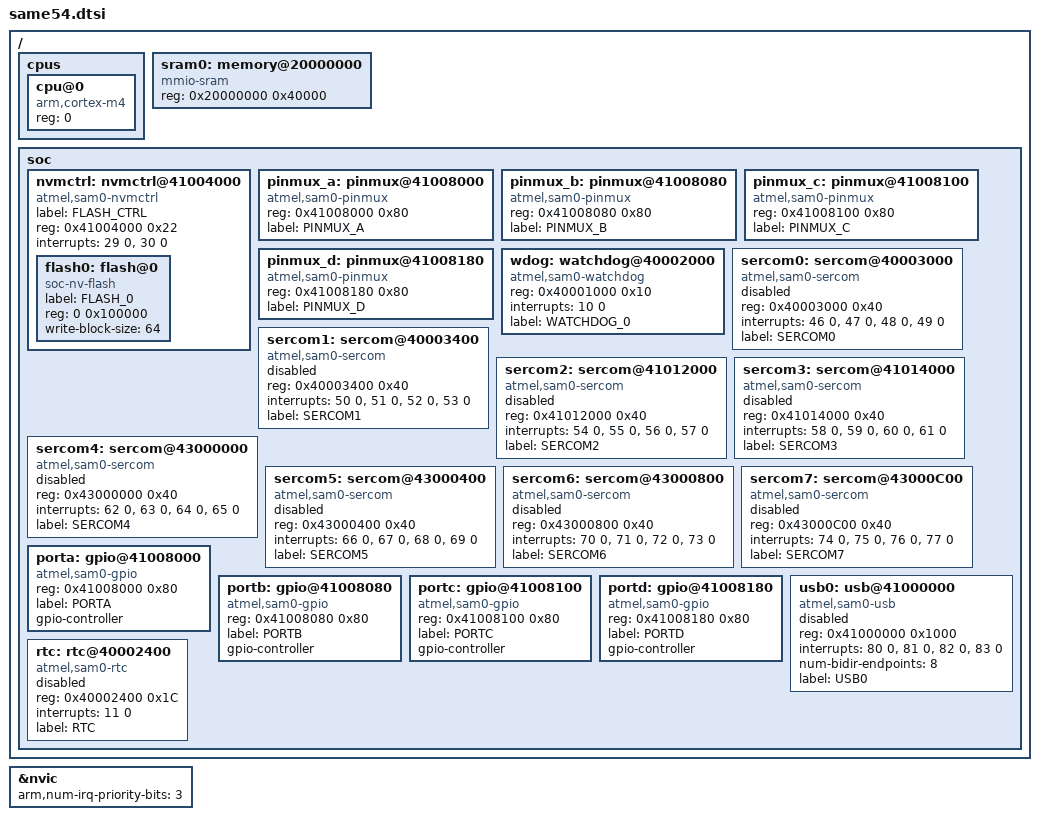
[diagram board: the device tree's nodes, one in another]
/*
 * Copyright (c) 2019 ML!PA Consulting GmbH
 *
 * SPDX-License-Identifier: Apache-2.0
 */

#include <arm/armv7-m.dtsi>
#include <dt-bindings/gpio/gpio.h>

/ {
	cpus {
		#address-cells = <1>;
		#size-cells = <0>;

		cpu@0 {
			device_type = "cpu";
			compatible = "arm,cortex-m4";
			reg = <0>;
		};
	};

	sram0: memory@20000000 {
		device_type = "memory";
		compatible = "mmio-sram";
		reg = <0x20000000 0x40000>;
	};

	soc {
		nvmctrl: nvmctrl@41004000  {
			compatible = "atmel,sam0-nvmctrl";
			label = "FLASH_CTRL";
			reg = <0x41004000 0x22>;
			interrupts = <29 0>, <30 0>;

			#address-cells = <1>;
			#size-cells = <1>;

			flash0: flash@0 {
				compatible = "soc-nv-flash";
				label = "FLASH_0";
				reg = <0 0x100000>;
				write-block-size = <64>;
			};
		};

		pinmux_a: pinmux@41008000 {
			compatible = "atmel,sam0-pinmux";
			reg = <0x41008000 0x80>;
			label = "PINMUX_A";
		};

		pinmux_b: pinmux@41008080 {
			compatible = "atmel,sam0-pinmux";
			reg = <0x41008080 0x80>;
			label = "PINMUX_B";
		};

		pinmux_c: pinmux@41008100 {
			compatible = "atmel,sam0-pinmux";
			reg = <0x41008100 0x80>;
			label = "PINMUX_C";
		};

		pinmux_d: pinmux@41008180 {
			compatible = "atmel,sam0-pinmux";
			reg = <0x41008180 0x80>;
			label = "PINMUX_D";
		};

		wdog: watchdog@40002000 {
			compatible = "atmel,sam0-watchdog";
			reg = <0x40001000 0x10>;
			interrupts = <10 0>;
			label = "WATCHDOG_0";
		};

		sercom0: sercom@40003000 {
			compatible = "atmel,sam0-sercom";
			reg = <0x40003000 0x40>;
			interrupts = <46 0>, <47 0>, <48 0>, <49 0>;
			status = "disabled";
			label = "SERCOM0";
		};

		sercom1: sercom@40003400 {
			compatible = "atmel,sam0-sercom";
			reg = <0x40003400 0x40>;
			interrupts = <50 0>, <51 0>, <52 0>, <53 0>;
			status = "disabled";
			label = "SERCOM1";
		};

		sercom2: sercom@41012000 {
			compatible = "atmel,sam0-sercom";
			reg = <0x41012000 0x40>;
			interrupts = <54 0>, <55 0>, <56 0>, <57 0>;
			status = "disabled";
			label = "SERCOM2";
		};

		sercom3: sercom@41014000 {
			compatible = "atmel,sam0-sercom";
			reg = <0x41014000 0x40>;
			interrupts = <58 0>, <59 0>, <60 0>, <61 0>;
			status = "disabled";
			label = "SERCOM3";
		};

		sercom4: sercom@43000000 {
			compatible = "atmel,sam0-sercom";
			reg = <0x43000000 0x40>;
			interrupts = <62 0>, <63 0>, <64 0>, <65 0>;
			status = "disabled";
			label = "SERCOM4";
		};

		sercom5: sercom@43000400 {
			compatible = "atmel,sam0-sercom";
			reg = <0x43000400 0x40>;
			interrupts = <66 0>, <67 0>, <68 0>, <69 0>;
			status = "disabled";
			label = "SERCOM5";
		};

		sercom6: sercom@43000800 {
			compatible = "atmel,sam0-sercom";
			reg = <0x43000800 0x40>;
			interrupts = <70 0>, <71 0>, <72 0>, <73 0>;
			status = "disabled";
			label = "SERCOM6";
		};

		sercom7: sercom@43000C00 {
			compatible = "atmel,sam0-sercom";
			reg = <0x43000C00 0x40>;
			interrupts = <74 0>, <75 0>, <76 0>, <77 0>;
			status = "disabled";
			label = "SERCOM7";
		};

		porta: gpio@41008000 {
			compatible = "atmel,sam0-gpio";
			reg = <0x41008000 0x80>;
			label = "PORTA";
			gpio-controller;
			#gpio-cells = <2>;
		};

		portb: gpio@41008080 {
			compatible = "atmel,sam0-gpio";
			reg = <0x41008080 0x80>;
			label = "PORTB";
			gpio-controller;
			#gpio-cells = <2>;
		};

		portc: gpio@41008100 {
			compatible = "atmel,sam0-gpio";
			reg = <0x41008100 0x80>;
			label = "PORTC";
			gpio-controller;
			#gpio-cells = <2>;
		};

		portd: gpio@41008180 {
			compatible = "atmel,sam0-gpio";
			reg = <0x41008180 0x80>;
			label = "PORTD";
			gpio-controller;
			#gpio-cells = <2>;
		};

		usb0: usb@41000000 {
			compatible = "atmel,sam0-usb";
			status = "disabled";
			reg = <0x41000000 0x1000>;
			interrupts = <80 0>, <81 0>, <82 0>, <83 0>;
			num-bidir-endpoints = <8>;
			label = "USB0";
		};

		rtc: rtc@40002400 {
			compatible = "atmel,sam0-rtc";
			reg = <0x40002400 0x1C>;
			interrupts = <11 0>;
			status = "disabled";
			label = "RTC";
		};
	};
};

&nvic {
	arm,num-irq-priority-bits = <3>;
};
